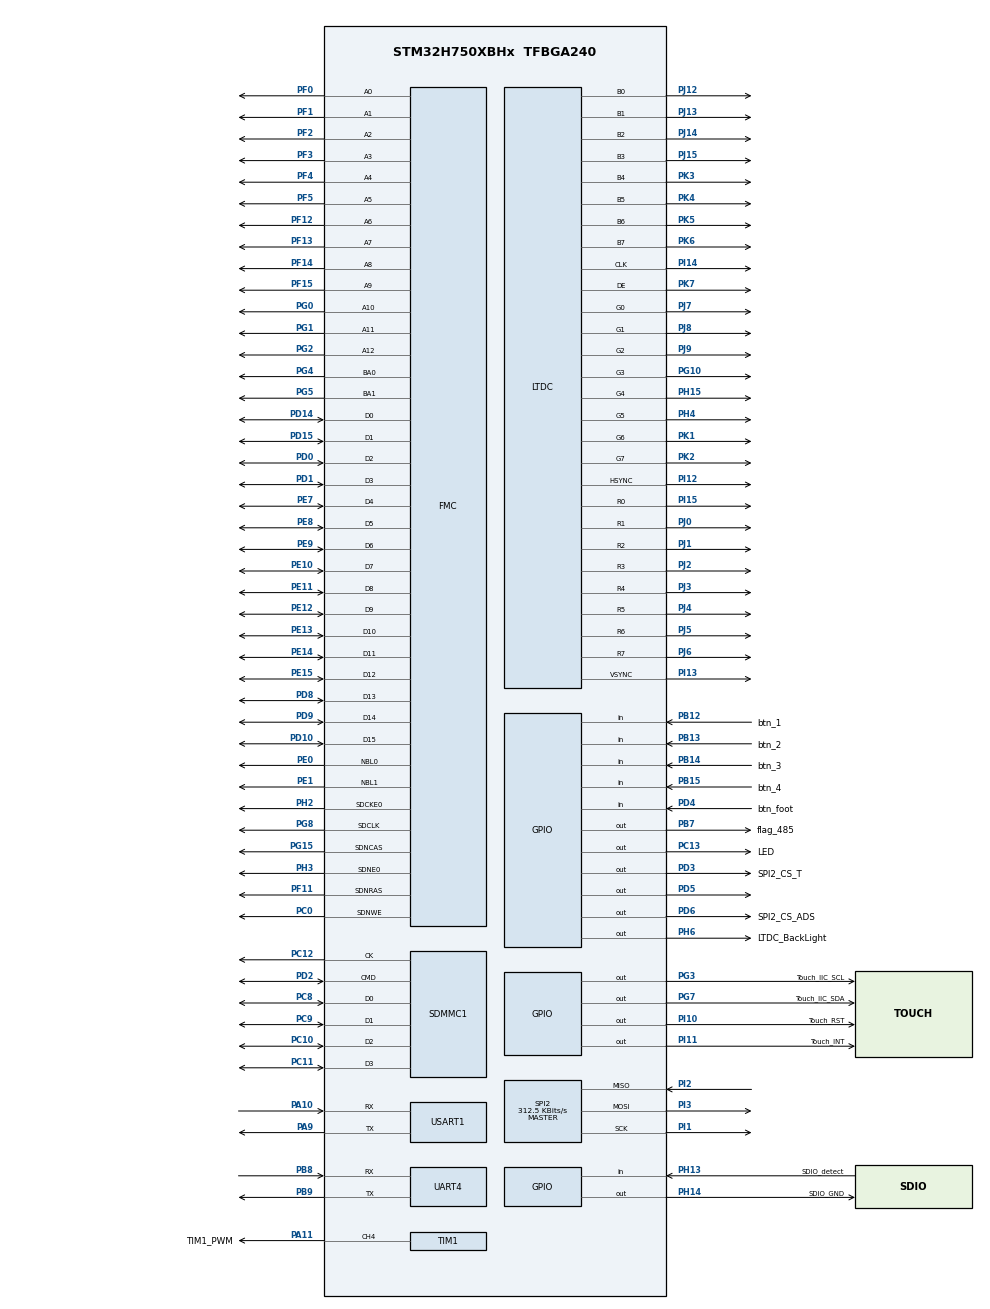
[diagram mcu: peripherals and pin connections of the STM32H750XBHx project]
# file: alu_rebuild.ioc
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CORTEX_M7.AccessPermission-Cortex_Memory_Protection_Unit_Region2_Settings=MPU_REGION_FULL_ACCESS
CORTEX_M7.BaseAddress-Cortex_Memory_Protection_Unit_Region2_Settings=0xC0000000
CORTEX_M7.BaseAddress_Spec=0xC0000000
CORTEX_M7.CPU_DCache=Disabled
CORTEX_M7.CPU_ICache=Enabled
CORTEX_M7.Enable-Cortex_Memory_Protection_Unit_Region2_Settings=MPU_REGION_ENABLE
CORTEX_M7.Enable_Spec=__NULL
CORTEX_M7.IsCacheable-Cortex_Memory_Protection_Unit_Region2_Settings=MPU_ACCESS_CACHEABLE
CORTEX_M7.MPU_Control=MPU_PRIVILEGED_DEFAULT
CORTEX_M7.Size-Cortex_Memory_Protection_Unit_Region2_Settings=MPU_REGION_SIZE_32MB
CORTEX_M7.Size_Spec=MPU_REGION_SIZE_32MB
CORTEX_M7.SubRegionDisable-Cortex_Memory_Protection_Unit_Region2_Settings=0x00
DMA2D.ChromaSubSamplingForeground=DMA2D_NO_CSS
DMA2D.ColorMode=DMA2D_OUTPUT_RGB565
DMA2D.RedBlueSwapForeground=DMA2D_RB_REGULAR
FATFS.BSP.number=1
FATFS._CODE_PAGE=936
FATFS._MAX_SS=512
FATFS._USE_LABEL=1
FATFS._USE_LFN=2
FATFS0.BSP.STBoard=false
FATFS0.BSP.api=Unknown
FATFS0.BSP.instance=PH13
FATFS0.BSP.ip=GPIO
FATFS0.BSP.mode=Input
FATFS0.BSP.name=Detect_SDIO
FATFS0.BSP.solution=PH13
FMC.CASLatency1=FMC_SDRAM_CAS_LATENCY_3
FMC.ColumnBitsNumber1=FMC_SDRAM_COLUMN_BITS_NUM_9
FMC.ExitSelfRefreshDelay1=7
FMC.LoadToActiveDelay1=2
FMC.RCDDelay1=2
FMC.RPDelay1=2
FMC.ReadBurst1=FMC_SDRAM_RBURST_ENABLE
FMC.ReadPipeDelay1=FMC_SDRAM_RPIPE_DELAY_1
FMC.RowCycleDelay1=7
FMC.SDClockPeriod1=FMC_SDRAM_CLOCK_PERIOD_2
FMC.SelfRefreshTime1=4
FMC.WriteRecoveryTime1=3
FREERTOS.BinarySemaphores01=alu_temperature,Dynamic,NULL,;alu_threshold,Dynamic,NULL,;alu_screen,Dynamic,NULL,;alu_choose,Dynamic,NULL,;alu_savename,Dynamic,NULL,;Sem_10ms,Dynamic,NULL,Available
FREERTOS.INCLUDE_uxTaskGetStackHighWaterMark=1
FREERTOS.INCLUDE_xTimerPendFunctionCall=1
FREERTOS.Queues01=alu_temp_list,100,uint32_t,0,Dynamic,NULL,NULL
FREERTOS.Tasks01=defaultTask,0,1536,StartTouchGFX,As weak,NULL,Dynamic,NULL,NULL;aluMain,0,1536,AluMain,As weak,NULL,Dynamic,NULL,NULL;aluSubProgress,1,1536,AluSubProgress,As weak,NULL,Dynamic,NULL,NULL;Task_Control,3,1024,StartTask_Control,As weak,NULL,Dynamic,NULL,NULL
FREERTOS.configTIMER_TASK_STACK_DEPTH=4096
FREERTOS.configTOTAL_HEAP_SIZE=32768
LTDC.ActiveW=800
LTDC.Alpha_L0=255
LTDC.FBStartAdress_L0=0xC0000000
LTDC.HBP=80
LTDC.HFP=200
LTDC.HSync=1
LTDC.ImageHeight_L0=480
LTDC.ImageWidth_L0=800
LTDC.Layers=0
LTDC.PixelFormat_L0=LTDC_PIXEL_FORMAT_RGB565
LTDC.VBP=40
LTDC.VFP=22
LTDC.VSync=1
LTDC.WindowX1_L0=800
LTDC.WindowY1_L0=480
Mcu.Family=STM32H7
Mcu.Name=STM32H750XBHx
Mcu.Package=TFBGA240
Mdma.MDMA_Channel0.Request0=SDMMC1_END_DATA
Mdma.MDMA_Channel0.RequestsNb=1
Mdma.MDMA_Channel0.SDMMC1_END_DATA.0.BlockCount=0
Mdma.MDMA_Channel0.SDMMC1_END_DATA.0.BlockDataLength=0
Mdma.MDMA_Channel0.SDMMC1_END_DATA.0.BufferTransferLength=1
Mdma.MDMA_Channel0.SDMMC1_END_DATA.0.CircularMode=MDMA_LINEAR_LIST
Mdma.MDMA_Channel0.SDMMC1_END_DATA.0.DataAlignment=MDMA_DATAALIGN_PACKENABLE
Mdma.MDMA_Channel0.SDMMC1_END_DATA.0.DestBlockAddressOffset=0
Mdma.MDMA_Channel0.SDMMC1_END_DATA.0.DestBurst=MDMA_DEST_BURST_SINGLE
Mdma.MDMA_Channel0.SDMMC1_END_DATA.0.DestDataSize=MDMA_DEST_DATASIZE_BYTE
Mdma.MDMA_Channel0.SDMMC1_END_DATA.0.DestinationInc=MDMA_DEST_INC_BYTE
Mdma.MDMA_Channel0.SDMMC1_END_DATA.0.DstAddress=0
Mdma.MDMA_Channel0.SDMMC1_END_DATA.0.Endianness=MDMA_LITTLE_ENDIANNESS_PRESERVE
Mdma.MDMA_Channel0.SDMMC1_END_DATA.0.Instance=MDMA_Channel0
Mdma.MDMA_Channel0.SDMMC1_END_DATA.0.MaskAddress=0
Mdma.MDMA_Channel0.SDMMC1_END_DATA.0.MaskData=0
Mdma.MDMA_Channel0.SDMMC1_END_DATA.0.Priority=MDMA_PRIORITY_HIGH
Mdma.MDMA_Channel0.SDMMC1_END_DATA.0.Rank=First
Mdma.MDMA_Channel0.SDMMC1_END_DATA.0.SourceBlockAddressOffset=0
Mdma.MDMA_Channel0.SDMMC1_END_DATA.0.SourceBurst=MDMA_SOURCE_BURST_SINGLE
Mdma.MDMA_Channel0.SDMMC1_END_DATA.0.SourceDataSize=MDMA_SRC_DATASIZE_BYTE
Mdma.MDMA_Channel0.SDMMC1_END_DATA.0.SourceInc=MDMA_SRC_INC_BYTE
Mdma.MDMA_Channel0.SDMMC1_END_DATA.0.SrcAddress=0
Mdma.MDMA_Channel0.SDMMC1_END_DATA.0.TransferTriggerMode=MDMA_BUFFER_TRANSFER
Mdma.RequestSet0=MDMA_Channel0
Mdma.RequestSetsNb=1
NVIC.DMA2D_IRQn=true\:5\:0\:true\:false\:true\:true\:true\:true\:true
NVIC.LTDC_IRQn=true\:5\:0\:true\:false\:true\:true\:true\:true\:true
NVIC.MDMA_IRQn=true\:5\:0\:true\:false\:true\:true\:true\:true\:true
NVIC.PriorityGroup=NVIC_PRIORITYGROUP_4
NVIC.SDMMC1_IRQn=true\:5\:0\:true\:false\:true\:true\:true\:true\:true
NVIC.TIM17_IRQn=true\:15\:0\:true\:false\:true\:false\:false\:true\:true
NVIC.TIM7_IRQn=true\:5\:0\:false\:false\:true\:true\:true\:true\:true
NVIC.TimeBase=TIM17_IRQn
NVIC.TimeBaseIP=TIM17
NVIC.USART1_IRQn=true\:5\:0\:false\:false\:true\:true\:true\:true\:true
PA10.Mode=Asynchronous
PA10.Signal=USART1_RX
PA11.GPIO_Label=TIM1_PWM
PA11.GPIO_Speed=GPIO_SPEED_FREQ_HIGH
PA11.Signal=S_TIM1_CH4
PA13\ (JTMS/SWDIO).Mode=Serial_Wire
PA13\ (JTMS/SWDIO).Signal=DEBUG_JTMS-SWDIO
PA14\ (JTCK/SWCLK).Mode=Serial_Wire
PA14\ (JTCK/SWCLK).Signal=DEBUG_JTCK-SWCLK
PA9.Mode=Asynchronous
PA9.Signal=USART1_TX
PB12.GPIO_Label=btn_1
PB12.GPIO_PuPd=GPIO_PULLUP
PB12.Signal=GPIO_Input
PB13.GPIO_Label=btn_2
PB13.GPIO_PuPd=GPIO_PULLUP
PB13.Signal=GPIO_Input
PB14.GPIO_Label=btn_3
PB14.GPIO_PuPd=GPIO_PULLUP
PB14.Signal=GPIO_Input
PB15.GPIO_Label=btn_4
PB15.GPIO_PuPd=GPIO_PULLUP
PB15.Signal=GPIO_Input
PB7.GPIO_Label=flag_485
PB7.GPIO_Speed=GPIO_SPEED_FREQ_HIGH
PB7.PinState=GPIO_PIN_SET
PB7.Signal=GPIO_Output
PB8.Mode=Asynchronous
PB8.Signal=UART4_RX
PB9.Mode=Asynchronous
PB9.Signal=UART4_TX
PC0.Signal=FMC_SDNWE
PC10.Mode=SD_4_bits_Wide_bus
PC10.Signal=SDMMC1_D2
PC11.Mode=SD_4_bits_Wide_bus
PC11.Signal=SDMMC1_D3
PC12.Mode=SD_4_bits_Wide_bus
PC12.Signal=SDMMC1_CK
PC13.GPIO_Label=LED
PC13.PinState=GPIO_PIN_SET
PC13.Signal=GPIO_Output
PC14-OSC32_IN\ (OSC32_IN).Mode=LSE-External-Oscillator
PC14-OSC32_IN\ (OSC32_IN).Signal=RCC_OSC32_IN
PC15-OSC32_OUT\ (OSC32_OUT).Mode=LSE-External-Oscillator
PC15-OSC32_OUT\ (OSC32_OUT).Signal=RCC_OSC32_OUT
PC8.Mode=SD_4_bits_Wide_bus
PC8.Signal=SDMMC1_D0
PC9.Mode=SD_4_bits_Wide_bus
PC9.Signal=SDMMC1_D1
PD0.Signal=FMC_D2_DA2
PD1.Signal=FMC_D3_DA3
PD10.Signal=FMC_D15_DA15
PD14.Signal=FMC_D0_DA0
PD15.Signal=FMC_D1_DA1
PD2.Mode=SD_4_bits_Wide_bus
PD2.Signal=SDMMC1_CMD
PD3.GPIO_Label=SPI2_CS_T
PD3.GPIO_PuPd=GPIO_NOPULL
PD3.GPIO_Speed=GPIO_SPEED_FREQ_MEDIUM
PD3.PinState=GPIO_PIN_SET
PD3.Signal=GPIO_Output
PD4.GPIO_Label=btn_foot
PD4.GPIO_PuPd=GPIO_PULLDOWN
PD4.Signal=GPIO_Input
PD5.GPIO_Speed=GPIO_SPEED_FREQ_MEDIUM
PD5.PinState=GPIO_PIN_SET
PD5.Signal=GPIO_Output
PD6.GPIO_Label=SPI2_CS_ADS
PD6.GPIO_PuPd=GPIO_NOPULL
PD6.GPIO_Speed=GPIO_SPEED_FREQ_MEDIUM
PD6.PinState=GPIO_PIN_SET
PD6.Signal=GPIO_Output
PD8.Signal=FMC_D13_DA13
PD9.Signal=FMC_D14_DA14
PE0.Signal=FMC_NBL0
PE1.Signal=FMC_NBL1
PE10.Signal=FMC_D7_DA7
PE11.Signal=FMC_D8_DA8
PE12.Signal=FMC_D9_DA9
PE13.Signal=FMC_D10_DA10
PE14.Signal=FMC_D11_DA11
PE15.Signal=FMC_D12_DA12
PE7.Signal=FMC_D4_DA4
PE8.Signal=FMC_D5_DA5
PE9.Signal=FMC_D6_DA6
PF0.Signal=FMC_A0
PF1.Signal=FMC_A1
PF11.Signal=FMC_SDNRAS
PF12.Signal=FMC_A6
PF13.Signal=FMC_A7
PF14.Signal=FMC_A8
PF15.Signal=FMC_A9
PF2.Signal=FMC_A2
PF3.Signal=FMC_A3
PF4.Signal=FMC_A4
PF5.Signal=FMC_A5
PG0.Signal=FMC_A10
PG1.Signal=FMC_A11
PG10.GPIO_Speed=GPIO_SPEED_FREQ_VERY_HIGH
PG10.Mode=RGB888
PG10.Signal=LTDC_G3
PG15.Signal=FMC_SDNCAS
PG2.Signal=FMC_A12
PG3.GPIO_Label=Touch_IIC_SCL
PG3.GPIO_ModeDefaultOutputPP=GPIO_MODE_OUTPUT_OD
PG3.GPIO_PuPd=GPIO_NOPULL
PG3.PinState=GPIO_PIN_SET
PG3.Signal=GPIO_Output
PG4.Signal=FMC_A14_BA0
PG5.Signal=FMC_A15_BA1
PG7.GPIO_Label=Touch_IIC_SDA
PG7.GPIO_ModeDefaultOutputPP=GPIO_MODE_OUTPUT_OD
PG7.GPIO_PuPd=GPIO_NOPULL
PG7.PinState=GPIO_PIN_SET
PG7.Signal=GPIO_Output
PG8.Signal=FMC_SDCLK
PH0-OSC_IN\ (PH0).Mode=HSE-External-Oscillator
PH0-OSC_IN\ (PH0).Signal=RCC_OSC_IN
PH1-OSC_OUT\ (PH1).Mode=HSE-External-Oscillator
PH1-OSC_OUT\ (PH1).Signal=RCC_OSC_OUT
PH13.GPIO_Label=SDIO_detect
PH13.GPIO_PuPd=GPIO_PULLDOWN
PH13.Signal=GPIO_Input
PH14.GPIO_Label=SDIO_GND
PH14.GPIO_PuPd=GPIO_PULLDOWN
PH14.GPIO_Speed=GPIO_SPEED_FREQ_VERY_HIGH
PH14.PinState=GPIO_PIN_RESET
PH14.Signal=GPIO_Output
PH15.GPIO_Speed=GPIO_SPEED_FREQ_VERY_HIGH
PH15.Mode=RGB888
PH15.Signal=LTDC_G4
PH2.Mode=SdramChipSelect1_1
PH2.Signal=FMC_SDCKE0
PH3.Mode=SdramChipSelect1_1
PH3.Signal=FMC_SDNE0
PH4.GPIO_Speed=GPIO_SPEED_FREQ_VERY_HIGH
PH4.Mode=RGB888
PH4.Signal=LTDC_G5
PH6.GPIO_Label=LTDC_BackLight
PH6.GPIO_Speed=GPIO_SPEED_FREQ_LOW
PH6.PinState=GPIO_PIN_RESET
PH6.Signal=GPIO_Output
PI1.Mode=Full_Duplex_Master
PI1.Signal=SPI2_SCK
PI10.GPIO_Label=Touch_RST
PI10.GPIO_PuPd=GPIO_PULLUP
PI10.PinState=GPIO_PIN_SET
PI10.Signal=GPIO_Output
PI11.GPIO_Label=Touch_INT
PI11.GPIO_PuPd=GPIO_PULLUP
PI11.Signal=GPIO_Output
PI12.GPIO_Speed=GPIO_SPEED_FREQ_VERY_HIGH
PI12.Mode=RGB888
PI12.Signal=LTDC_HSYNC
PI13.GPIO_Speed=GPIO_SPEED_FREQ_VERY_HIGH
PI13.Mode=RGB888
PI13.Signal=LTDC_VSYNC
PI14.GPIO_Speed=GPIO_SPEED_FREQ_VERY_HIGH
PI14.Mode=RGB888
PI14.Signal=LTDC_CLK
PI15.GPIO_Speed=GPIO_SPEED_FREQ_VERY_HIGH
PI15.Mode=RGB888
PI15.Signal=LTDC_R0
PI2.Mode=Full_Duplex_Master
PI2.Signal=SPI2_MISO
PI3.Mode=Full_Duplex_Master
PI3.Signal=SPI2_MOSI
PJ0.GPIO_Speed=GPIO_SPEED_FREQ_VERY_HIGH
PJ0.Mode=RGB888
PJ0.Signal=LTDC_R1
PJ1.GPIO_Speed=GPIO_SPEED_FREQ_VERY_HIGH
PJ1.Mode=RGB888
PJ1.Signal=LTDC_R2
PJ12.GPIO_Speed=GPIO_SPEED_FREQ_VERY_HIGH
PJ12.Mode=RGB888
PJ12.Signal=LTDC_B0
PJ13.GPIO_Speed=GPIO_SPEED_FREQ_VERY_HIGH
PJ13.Mode=RGB888
PJ13.Signal=LTDC_B1
PJ14.GPIO_Speed=GPIO_SPEED_FREQ_VERY_HIGH
PJ14.Mode=RGB888
PJ14.Signal=LTDC_B2
PJ15.GPIO_Speed=GPIO_SPEED_FREQ_VERY_HIGH
PJ15.Mode=RGB888
PJ15.Signal=LTDC_B3
PJ2.GPIO_Speed=GPIO_SPEED_FREQ_VERY_HIGH
PJ2.Mode=RGB888
PJ2.Signal=LTDC_R3
PJ3.GPIO_Speed=GPIO_SPEED_FREQ_VERY_HIGH
PJ3.Mode=RGB888
PJ3.Signal=LTDC_R4
PJ4.GPIO_Speed=GPIO_SPEED_FREQ_VERY_HIGH
PJ4.Mode=RGB888
PJ4.Signal=LTDC_R5
PJ5.GPIO_Speed=GPIO_SPEED_FREQ_VERY_HIGH
PJ5.Mode=RGB888
PJ5.Signal=LTDC_R6
PJ6.GPIO_Speed=GPIO_SPEED_FREQ_VERY_HIGH
PJ6.Mode=RGB888
PJ6.Signal=LTDC_R7
PJ7.GPIO_Speed=GPIO_SPEED_FREQ_VERY_HIGH
PJ7.Mode=RGB888
PJ7.Signal=LTDC_G0
PJ8.GPIO_Speed=GPIO_SPEED_FREQ_VERY_HIGH
PJ8.Mode=RGB888
PJ8.Signal=LTDC_G1
PJ9.GPIO_Speed=GPIO_SPEED_FREQ_VERY_HIGH
PJ9.Mode=RGB888
PJ9.Signal=LTDC_G2
PK1.GPIO_Speed=GPIO_SPEED_FREQ_VERY_HIGH
PK1.Mode=RGB888
PK1.Signal=LTDC_G6
PK2.GPIO_Speed=GPIO_SPEED_FREQ_VERY_HIGH
PK2.Mode=RGB888
PK2.Signal=LTDC_G7
PK3.GPIO_Speed=GPIO_SPEED_FREQ_VERY_HIGH
PK3.Mode=RGB888
PK3.Signal=LTDC_B4
PK4.GPIO_Speed=GPIO_SPEED_FREQ_VERY_HIGH
PK4.Mode=RGB888
PK4.Signal=LTDC_B5
PK5.GPIO_Speed=GPIO_SPEED_FREQ_VERY_HIGH
PK5.Mode=RGB888
PK5.Signal=LTDC_B6
PK6.GPIO_Speed=GPIO_SPEED_FREQ_VERY_HIGH
PK6.Mode=RGB888
PK6.Signal=LTDC_B7
PK7.GPIO_Speed=GPIO_SPEED_FREQ_VERY_HIGH
PK7.Mode=RGB888
PK7.Signal=LTDC_DE
ProjectManager.HeapSize=0x2000
ProjectManager.StackSize=0x4000
ProjectManager.TargetToolchain=MDK-ARM V5.32
RCC.ADCFreq_Value=40000000
RCC.APB1Freq_Value=120000000
RCC.APB2Freq_Value=120000000
RCC.APB3Freq_Value=120000000
RCC.APB4Freq_Value=120000000
RCC.CortexFreq_Value=480000000
RCC.D1PPRE=RCC_APB3_DIV2
RCC.D2PPRE1=RCC_APB1_DIV2
RCC.D2PPRE2=RCC_APB2_DIV2
RCC.D3PPRE=RCC_APB4_DIV2
RCC.DIVM1=5
RCC.DIVM2=10
RCC.DIVM3=25
RCC.DIVN1=192
RCC.DIVN2=160
RCC.DIVN3=330
RCC.DIVP2=10
RCC.DIVQ1=4
RCC.DIVR3=10
RCC.HCLKFreq_Value=240000000
RCC.HPRE=RCC_HCLK_DIV2
RCC.PLLSourceVirtual=RCC_PLLSOURCE_HSE
RCC.SPI123CLockSelection=RCC_SPI123CLKSOURCE_PLL2
RCC.SYSCLKFreq_VALUE=480000000
RCC.SYSCLKSource=RCC_SYSCLKSOURCE_PLLCLK
RCC.USBFreq_Value=240000000
SDMMC1.ClockDiv=6
SH.FMC_A0.0=FMC_A0,13b-sda1
SH.FMC_A1.0=FMC_A1,13b-sda1
SH.FMC_A10.0=FMC_A10,13b-sda1
SH.FMC_A11.0=FMC_A11,13b-sda1
SH.FMC_A12.0=FMC_A12,13b-sda1
SH.FMC_A14_BA0.0=FMC_BA0,FourSdramBanks1
SH.FMC_A15_BA1.0=FMC_BA1,FourSdramBanks1
SH.FMC_A2.0=FMC_A2,13b-sda1
SH.FMC_A3.0=FMC_A3,13b-sda1
SH.FMC_A4.0=FMC_A4,13b-sda1
SH.FMC_A5.0=FMC_A5,13b-sda1
SH.FMC_A6.0=FMC_A6,13b-sda1
SH.FMC_A7.0=FMC_A7,13b-sda1
SH.FMC_A8.0=FMC_A8,13b-sda1
SH.FMC_A9.0=FMC_A9,13b-sda1
SH.FMC_D0_DA0.0=FMC_D0,sd-16b-d1
SH.FMC_D10_DA10.0=FMC_D10,sd-16b-d1
SH.FMC_D11_DA11.0=FMC_D11,sd-16b-d1
SH.FMC_D12_DA12.0=FMC_D12,sd-16b-d1
SH.FMC_D13_DA13.0=FMC_D13,sd-16b-d1
SH.FMC_D14_DA14.0=FMC_D14,sd-16b-d1
SH.FMC_D15_DA15.0=FMC_D15,sd-16b-d1
SH.FMC_D1_DA1.0=FMC_D1,sd-16b-d1
SH.FMC_D2_DA2.0=FMC_D2,sd-16b-d1
SH.FMC_D3_DA3.0=FMC_D3,sd-16b-d1
SH.FMC_D4_DA4.0=FMC_D4,sd-16b-d1
SH.FMC_D5_DA5.0=FMC_D5,sd-16b-d1
SH.FMC_D6_DA6.0=FMC_D6,sd-16b-d1
SH.FMC_D7_DA7.0=FMC_D7,sd-16b-d1
SH.FMC_D8_DA8.0=FMC_D8,sd-16b-d1
SH.FMC_D9_DA9.0=FMC_D9,sd-16b-d1
SH.FMC_NBL0.0=FMC_NBL0,Sd2ByteEnable1
SH.FMC_NBL1.0=FMC_NBL1,Sd2ByteEnable1
SH.FMC_SDCLK.0=FMC_SDCLK,13b-sda1
SH.FMC_SDNCAS.0=FMC_SDNCAS,13b-sda1
SH.FMC_SDNRAS.0=FMC_SDNRAS,13b-sda1
SH.FMC_SDNWE.0=FMC_SDNWE,13b-sda1
SH.S_TIM1_CH4.0=TIM1_CH4,PWM Generation4 CH4
SPI2.BaudRatePrescaler=SPI_BAUDRATEPRESCALER_128
SPI2.CLKPhase=SPI_PHASE_2EDGE
SPI2.CalculateBaudRate=312.5 KBits/s
SPI2.DataSize=SPI_DATASIZE_8BIT
SPI2.Direction=SPI_DIRECTION_2LINES
SPI2.Mode=SPI_MODE_MASTER
SPI2.VirtualType=VM_MASTER
STMicroelectronics.X-CUBE-TOUCHGFX.4.20.0.ApplicationCcGraphicsJjApplication=TouchGFXOoGenerator
STMicroelectronics.X-CUBE-TOUCHGFX.4.20.0.tgfx_address1=0xC0000000
STMicroelectronics.X-CUBE-TOUCHGFX.4.20.0.tgfx_address2=0xC00BB800
STMicroelectronics.X-CUBE-TOUCHGFX.4.20.0.tgfx_buffering_strategy=Double
STMicroelectronics.X-CUBE-TOUCHGFX.4.20.0.tgfx_display_interface=disp_ltdc
STMicroelectronics.X-CUBE-TOUCHGFX.4.20.0.tgfx_hardware_accelerator=dma_2d
STMicroelectronics.X-CUBE-TOUCHGFX.4.20.0.tgfx_location=By Address
STMicroelectronics.X-CUBE-TOUCHGFX.4.20.0.tgfx_vsync=vsync_ltdc
STMicroelectronics.X-CUBE-TOUCHGFX.4.20.0_IsPackSelfContextualization=true
TIM1.AutoReloadPreload=TIM_AUTORELOAD_PRELOAD_ENABLE
TIM1.Channel-PWM\ Generation4\ CH4=TIM_CHANNEL_4
TIM1.Period=1000-1
TIM1.Prescaler=240-1
TIM7.Period=999
TIM7.Prescaler=2399
USART1.VirtualMode-Asynchronous=VM_ASYNC
VP_CRC_VS_CRC.Mode=CRC_Activate
VP_DMA2D_VS_DMA2D.Mode=DMA2D_Activate
VP_FATFS_VS_SDIO.Mode=SDIO
VP_FREERTOS_VS_CMSIS_V1.Mode=CMSIS_V1
VP_STMicroelectronics.X-CUBE-TOUCHGFX_VS_GraphicsJjApplication_4.20.0.Mode=GraphicsJjApplication
VP_SYS_VS_tim17.Mode=TIM17
VP_TIM7_VS_ClockSourceINT.Mode=Enable_Timer
board=custom

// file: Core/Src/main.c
/* USER CODE BEGIN Header */
/**
  ******************************************************************************
  * @file           : main.c
  * @brief          : Main program body
  ******************************************************************************
  * @attention
  *
  * Copyright (c) 2024 STMicroelectronics.
  * All rights reserved.
  *
  * This software is licensed under terms that can be found in the LICENSE file
  * in the root directory of this software component.
  * If no LICENSE file comes with this software, it is provided AS-IS.
  ******************************************************************************
  *	@author          : Lv YiPin
	* @email           : AluminiumOxide@163.com
	* @SMA             : https://space.bilibili.com/87077691
  ******************************************************************************

  */
/* USER CODE END Header */
#include "main.h"
#include "cmsis_os.h"
#include "crc.h"
#include "dma2d.h"
#include "fatfs.h"
#include "ltdc.h"
#include "mdma.h"
#include "sdmmc.h"
#include "spi.h"
#include "tim.h"
#include "usart.h"
#include "gpio.h"
#include "fmc.h"
#include "app_touchgfx.h"

/* USER CODE BEGIN Includes */
#include "touch_800x480.h"
#include "alu_file.h"
#include "alu_temp.h"
#include "temp_filter.h"  // 新增：引入双通道测温组件
#include "alu_control.h"
//#include <stdio.h>
/* USER CODE END Includes */

void SystemClock_Config(void);
static void MPU_Initialize(void);
static void MPU_Config(void);
void MX_FREERTOS_Init(void);

/* USER CODE BEGIN 0 */
extern osSemaphoreId Sem_10msHandle;
/* USER CODE END 0 */

int main(void)
{
  /* USER CODE BEGIN 1 */
	SCB->VTOR = 0X90000000;       /* 程序大小超过flash大小，向量表重定位到片外 */

	// Icache开启后一定要关闭缓存回写刷新,Dcache开启后一定要清理,否则会导致FatFs挂载失败
  /* USER CODE END 1 */

  /* Enable I-Cache---------------------------------------------------------*/
  SCB_EnableICache();

  /* MCU Configuration--------------------------------------------------------*/

  /* Reset of all peripherals, Initializes the Flash interface and the Systick. */
  HAL_Init();

  /* MPU Configuration--------------------------------------------------------*/
  MPU_Config();

  /* Configure the system clock */
  SystemClock_Config();

  /* Initialize all configured peripherals */
  MX_GPIO_Init();
  MX_MDMA_Init();
  MX_LTDC_Init();
  MX_CRC_Init();
  MX_SPI2_Init();
  MX_FMC_Init();
  MX_DMA2D_Init();
  MX_SDMMC1_SD_Init();
  MX_FATFS_Init();
  MX_UART4_Init();
  MX_USART1_UART_Init();
  MX_TIM1_Init();
  MX_TIM7_Init();
  MX_TouchGFX_Init();
  /* Call PreOsInit function */
  MX_TouchGFX_PreOSInit();
  /* USER CODE BEGIN 2 */

	HAL_TIM_Base_Start_IT(&htim7);
	Touch_Init();				// 触摸屏初始化
	Alu_SD_mount();             // 判断FatFs是否挂载成功
  /* USER CODE END 2 */

  /* Call init function for freertos objects (in freertos.c) */
  MX_FREERTOS_Init();

  /* Start scheduler */
  osKernelStart();

  /* We should never get here as control is now taken by the scheduler */
  /* Infinite loop */
  while (1)
  {

  }
}

void SystemClock_Config(void)
{
  RCC_OscInitTypeDef RCC_OscInitStruct = {0};
  RCC_ClkInitTypeDef RCC_ClkInitStruct = {0};

  /** Supply configuration update enable
  */
  HAL_PWREx_ConfigSupply(PWR_LDO_SUPPLY);

  /** Configure the main internal regulator output voltage
  */

  while(!__HAL_PWR_GET_FLAG(PWR_FLAG_VOSRDY)) {}

  /** Initializes the RCC Oscillators according to the specified parameters
  * in the RCC_OscInitTypeDef structure.
  */
  RCC_OscInitStruct.OscillatorType = RCC_OSCILLATORTYPE_HSE;
  RCC_OscInitStruct.HSEState = RCC_HSE_ON;
  RCC_OscInitStruct.PLL.PLLState = RCC_PLL_ON;
  RCC_OscInitStruct.PLL.PLLSource = RCC_PLLSOURCE_HSE;
  RCC_OscInitStruct.PLL.PLLM = 5;
  RCC_OscInitStruct.PLL.PLLN = 192;
  RCC_OscInitStruct.PLL.PLLP = 2;
  RCC_OscInitStruct.PLL.PLLQ = 4;
  RCC_OscInitStruct.PLL.PLLR = 2;
  RCC_OscInitStruct.PLL.PLLRGE = RCC_PLL1VCIRANGE_2;
  RCC_OscInitStruct.PLL.PLLVCOSEL = RCC_PLL1VCOWIDE;
  RCC_OscInitStruct.PLL.PLLFRACN = 0;
  if (HAL_RCC_OscConfig(&RCC_OscInitStruct) != HAL_OK)
  {
    Error_Handler();
  }

  /** Initializes the CPU, AHB and APB buses clocks
  */
  RCC_ClkInitStruct.ClockType = RCC_CLOCKTYPE_HCLK|RCC_CLOCKTYPE_SYSCLK
                              |RCC_CLOCKTYPE_PCLK1|RCC_CLOCKTYPE_PCLK2
                              |RCC_CLOCKTYPE_D3PCLK1|RCC_CLOCKTYPE_D1PCLK1;
  RCC_ClkInitStruct.SYSCLKSource = RCC_SYSCLKSOURCE_PLLCLK;
  RCC_ClkInitStruct.SYSCLKDivider = RCC_SYSCLK_DIV1;
  RCC_ClkInitStruct.AHBCLKDivider = RCC_HCLK_DIV2;
  RCC_ClkInitStruct.APB3CLKDivider = RCC_APB3_DIV2;
  RCC_ClkInitStruct.APB1CLKDivider = RCC_APB1_DIV2;
  RCC_ClkInitStruct.APB2CLKDivider = RCC_APB2_DIV2;
  RCC_ClkInitStruct.APB4CLKDivider = RCC_APB4_DIV2;

  if (HAL_RCC_ClockConfig(&RCC_ClkInitStruct, FLASH_LATENCY_0) != HAL_OK)
  {
    Error_Handler();
  }
}

/* MPU Configuration */

void MPU_Config(void)
{
  MPU_Region_InitTypeDef MPU_InitStruct = {0};

  /* Disables the MPU */
  HAL_MPU_Disable();

  /** Initializes and configures the Region and the memory to be protected
  */
  MPU_InitStruct.Enable = MPU_REGION_ENABLE;
  MPU_InitStruct.Number = MPU_REGION_NUMBER2;
  MPU_InitStruct.BaseAddress = 0xC0000000;
  MPU_InitStruct.Size = MPU_REGION_SIZE_32MB;
  MPU_InitStruct.SubRegionDisable = 0x00;
  MPU_InitStruct.TypeExtField = MPU_TEX_LEVEL0;
  MPU_InitStruct.AccessPermission = MPU_REGION_FULL_ACCESS;
  MPU_InitStruct.DisableExec = MPU_INSTRUCTION_ACCESS_ENABLE;
  MPU_InitStruct.IsShareable = MPU_ACCESS_NOT_SHAREABLE;
  MPU_InitStruct.IsCacheable = MPU_ACCESS_CACHEABLE;
  MPU_InitStruct.IsBufferable = MPU_ACCESS_NOT_BUFFERABLE;

  HAL_MPU_ConfigRegion(&MPU_InitStruct);
  /* Enables the MPU */
  HAL_MPU_Enable(MPU_PRIVILEGED_DEFAULT);

}

void HAL_TIM_PeriodElapsedCallback(TIM_HandleTypeDef *htim)
{
  if (htim->Instance == TIM17) {
    HAL_IncTick();
  }
  /* USER CODE BEGIN Callback 1 */
  // ========================================================
  // 【新加】：如果是 TIM7 进来的中断 (严格的 10ms 到了)
  if (htim->Instance == TIM7) {
      // 释放信号量，把 Task_Control 任务叫醒去测温！
      osSemaphoreRelease(Sem_10msHandle);
  }
  // ========================================================

  /* USER CODE END Callback 1 */
}

void Error_Handler(void)
{
  __disable_irq();
  while (1)
  {
  }
}

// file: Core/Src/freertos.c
/* USER CODE BEGIN Header */
/**
  ******************************************************************************
  * File Name          : freertos.c
  * Description        : Code for freertos applications
  ******************************************************************************
  * @attention
  *
  * Copyright (c) 2024 STMicroelectronics.
  * All rights reserved.
  *
  * This software is licensed under terms that can be found in the LICENSE file
  * in the root directory of this software component.
  * If no LICENSE file comes with this software, it is provided AS-IS.
  *
  ******************************************************************************
  */
/* USER CODE END Header */

#include "FreeRTOS.h"
#include "task.h"
#include "main.h"
#include "cmsis_os.h"

/* USER CODE BEGIN Includes */
#include "app_touchgfx.h"
#include "temp_filter.h"
#include "alu_temp.h"
#include "alu_control.h"
#include "alu_file.h"
#include "task_control.h"
#include "alu_main.h"
#include <stdio.h>
/* USER CODE END Includes */

/* USER CODE BEGIN Variables */

/* 定义一个全局的 SD 卡写入队列句柄 */
QueueHandle_t SDWriteQueueHandle = NULL;

/* 定义一个全局的串口打印队列句柄 */
QueueHandle_t UARTPrintQueueHandle = NULL;

/* USER CODE END Variables */
osThreadId defaultTaskHandle;
osThreadId aluMainHandle;
osThreadId aluSubProgressHandle;
osThreadId Task_ControlHandle;
osMessageQId alu_temp_listHandle;
osSemaphoreId alu_temperatureHandle;
osSemaphoreId alu_thresholdHandle;
osSemaphoreId alu_screenHandle;
osSemaphoreId alu_chooseHandle;
osSemaphoreId alu_savenameHandle;
osSemaphoreId Sem_10msHandle;

void StartTouchGFX(void const * argument);
void AluMain(void const * argument);
void AluSubProgress(void const * argument);
void StartTask_Control(void const * argument);

void MX_FREERTOS_Init(void); /* (MISRA C 2004 rule 8.1) */

/* GetIdleTaskMemory prototype (linked to static allocation support) */
void vApplicationGetIdleTaskMemory( StaticTask_t **ppxIdleTaskTCBBuffer, StackType_t **ppxIdleTaskStackBuffer, uint32_t *pulIdleTaskStackSize );

/* GetTimerTaskMemory prototype (linked to static allocation support) */
void vApplicationGetTimerTaskMemory( StaticTask_t **ppxTimerTaskTCBBuffer, StackType_t **ppxTimerTaskStackBuffer, uint32_t *pulTimerTaskStackSize );

/* USER CODE BEGIN GET_IDLE_TASK_MEMORY */
static StaticTask_t xIdleTaskTCBBuffer;
static StackType_t xIdleStack[configMINIMAL_STACK_SIZE];

void vApplicationGetIdleTaskMemory( StaticTask_t **ppxIdleTaskTCBBuffer, StackType_t **ppxIdleTaskStackBuffer, uint32_t *pulIdleTaskStackSize )
{
  *ppxIdleTaskTCBBuffer = &xIdleTaskTCBBuffer;
  *ppxIdleTaskStackBuffer = &xIdleStack[0];
  *pulIdleTaskStackSize = configMINIMAL_STACK_SIZE;
  /* place for user code */
}
/* USER CODE END GET_IDLE_TASK_MEMORY */

/* USER CODE BEGIN GET_TIMER_TASK_MEMORY */
static StaticTask_t xTimerTaskTCBBuffer;
static StackType_t xTimerStack[configTIMER_TASK_STACK_DEPTH];

void vApplicationGetTimerTaskMemory( StaticTask_t **ppxTimerTaskTCBBuffer, StackType_t **ppxTimerTaskStackBuffer, uint32_t *pulTimerTaskStackSize )
{
  *ppxTimerTaskTCBBuffer = &xTimerTaskTCBBuffer;
  *ppxTimerTaskStackBuffer = &xTimerStack[0];
  *pulTimerTaskStackSize = configTIMER_TASK_STACK_DEPTH;
  /* place for user code */
}
/* USER CODE END GET_TIMER_TASK_MEMORY */

void MX_FREERTOS_Init(void) {

  /* Create the semaphores(s) */
  /* definition and creation of alu_temperature */
  osSemaphoreDef(alu_temperature);
  alu_temperatureHandle = osSemaphoreCreate(osSemaphore(alu_temperature), 1);

  /* definition and creation of alu_threshold */
  osSemaphoreDef(alu_threshold);
  alu_thresholdHandle = osSemaphoreCreate(osSemaphore(alu_threshold), 1);

  /* definition and creation of alu_screen */
  osSemaphoreDef(alu_screen);
  alu_screenHandle = osSemaphoreCreate(osSemaphore(alu_screen), 1);

  /* definition and creation of alu_choose */
  osSemaphoreDef(alu_choose);
  alu_chooseHandle = osSemaphoreCreate(osSemaphore(alu_choose), 1);

  /* definition and creation of alu_savename */
  osSemaphoreDef(alu_savename);
  alu_savenameHandle = osSemaphoreCreate(osSemaphore(alu_savename), 1);

  /* definition and creation of Sem_10ms */
  osSemaphoreDef(Sem_10ms);
  Sem_10msHandle = osSemaphoreCreate(osSemaphore(Sem_10ms), 1);

  /* Create the queue(s) */
  /* definition and creation of alu_temp_list */
  osMessageQDef(alu_temp_list, 100, uint32_t);
  alu_temp_listHandle = osMessageCreate(osMessageQ(alu_temp_list), NULL);

  /* USER CODE BEGIN RTOS_QUEUES */
  /* add queues, ... */
  /* 串口打印队列，长度40 */
  osMessageQDef(uart_print_queue, 40, UARTPrintData_t);
  UARTPrintQueueHandle = osMessageCreate(osMessageQ(uart_print_queue), NULL);
  /* USER CODE END RTOS_QUEUES */

  /* Create the thread(s) */
  /* definition and creation of defaultTask */
  osThreadDef(defaultTask, StartTouchGFX, osPriorityNormal, 0, 1536);
  defaultTaskHandle = osThreadCreate(osThread(defaultTask), NULL);

  /* definition and creation of aluMain */
  osThreadDef(aluMain, AluMain, osPriorityNormal, 0, 1536);
  aluMainHandle = osThreadCreate(osThread(aluMain), NULL);

  /* definition and creation of aluSubProgress */
  osThreadDef(aluSubProgress, AluSubProgress, osPriorityAboveNormal, 0, 1536);
  aluSubProgressHandle = osThreadCreate(osThread(aluSubProgress), NULL);

  /* definition and creation of Task_Control */
  osThreadDef(Task_Control, StartTask_Control, osPriorityRealtime, 0, 1024);
  Task_ControlHandle = osThreadCreate(osThread(Task_Control), NULL);

}

__weak void StartTouchGFX(void const * argument)
{
  for(;;)
  {
    osDelay(1);
  }
}

__weak void AluMain(void const * argument)
{
  for(;;)
  {
    osDelay(1);
  }
}

__weak void AluSubProgress(void const * argument)
{
  /* USER CODE BEGIN AluSubProgress */
  UARTPrintData_t rx_data;
  UARTPrintData_t print_buf[20];
  uint8_t buf_count = 0;
  uint32_t tick_count = 0;

  // 打印耗时统计变量
  uint32_t print_time_max = 0;
  uint32_t print_time_sum = 0;
  uint32_t print_time_cnt = 0;

  // 启用DWT循环计数器
  CoreDebug->DEMCR |= CoreDebug_DEMCR_TRCENA_Msk;
  DWT->CTRL |= DWT_CTRL_CYCCNTENA_Msk;

  for(;;)
  {
      tick_count++;

      // 等待队列数据，超时时间设为 10ms
      if (xQueueReceive(UARTPrintQueueHandle, &rx_data, 10) == pdPASS) {
          print_buf[buf_count++] = rx_data;

          // 如果攒够了20个数据（相当于200ms），一次性批量打印
          if (buf_count >= 20) {
              uint32_t start_time = DWT->CYCCNT;

              for (int i = 0; i < buf_count; i++) {
                  printf("[%u]%.2f,%.4g,%.4g,%.4g,%.2f\r\n",
                         print_buf[i].timestamp,
                         print_buf[i].current_temp,
                         print_buf[i].p_out,
                         print_buf[i].i_out,
                         print_buf[i].d_out * 100.0f,
                         print_buf[i].pwm_out);
              }

              uint32_t end_time = DWT->CYCCNT;
              uint32_t elapsed = (end_time >= start_time) ? (end_time - start_time) : (0xFFFFFFFF - start_time + end_time);
              print_time_sum += elapsed;
              print_time_cnt++;
              if (elapsed > print_time_max) {
                  print_time_max = elapsed;
              }

              buf_count = 0;
          }
      } else {
          // 如果10ms内没收到新数据，说明可能停止加热了。把缓存里剩下的数据强制打印出来
          if (buf_count > 0) {
              uint32_t start_time = DWT->CYCCNT;

              for (int i = 0; i < buf_count; i++) {
                  printf("[%lu]%.2f,%.4g,%.4g,%.4g,%.2f\r\n",
                         print_buf[i].timestamp,
                         print_buf[i].current_temp,
                         print_buf[i].p_out,
                         print_buf[i].i_out,
                         print_buf[i].d_out * 100.0f,
                         print_buf[i].pwm_out);
              }

              uint32_t end_time = DWT->CYCCNT;
              uint32_t elapsed = (end_time >= start_time) ? (end_time - start_time) : (0xFFFFFFFF - start_time + end_time);
              print_time_sum += elapsed;
              print_time_cnt++;
              if (elapsed > print_time_max) {
                  print_time_max = elapsed;
              }

              buf_count = 0;
          }
      }

      // 每100个循环（约1秒）打印一次耗时统计
      if (tick_count % 100 == 0) {
          if (enable_print_timing == 1 && print_time_cnt > 0) {
              float avg_us = (float)print_time_sum / print_time_cnt / (SystemCoreClock / 1000000.0f);
              float max_us = (float)print_time_max / (SystemCoreClock / 1000000.0f);
              printf("\r\n\r\n===== PRINT TIMING (1s) =====\r\n");
              printf("Max: %.1fus(%.0fcycles), Avg: %.1fus(%.0fcycles), Count: %u\r\n",
                     max_us, (float)print_time_max, avg_us, (float)print_time_sum / print_time_cnt, (unsigned int)print_time_cnt);
              printf("=============================\r\n\r\n");
          }

          // 每1秒打印一次堆栈信息，无论是否在加热状态
          if (enable_stack_print == 1) {
              printf("[STACK] aluMain:%u, defaultTask:%u, Control:%u, SubProg:%u\r\n",
                     (unsigned int)uxTaskGetStackHighWaterMark(aluMainHandle),
					 (unsigned int)uxTaskGetStackHighWaterMark(defaultTaskHandle),
                     (unsigned int)uxTaskGetStackHighWaterMark(Task_ControlHandle),
                     (unsigned int)uxTaskGetStackHighWaterMark(aluSubProgressHandle));
          }

          // 重置统计变量
          print_time_max = 0;
          print_time_sum = 0;
          print_time_cnt = 0;
      }
  }
  /* USER CODE END AluSubProgress */
}

__weak void StartTask_Control(void const * argument)
{
for(;;)
  {
    osDelay(1);
  }
}
